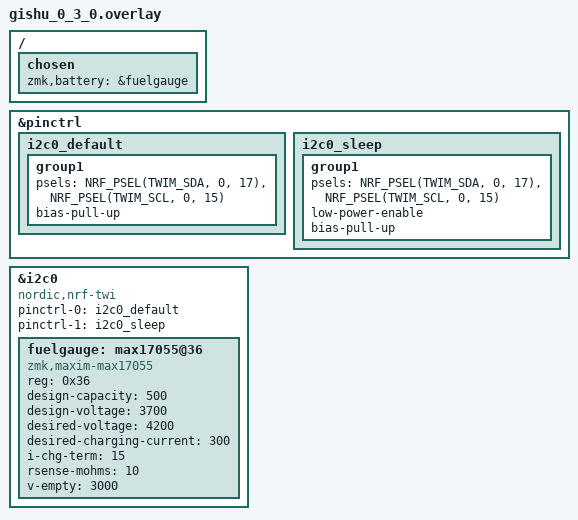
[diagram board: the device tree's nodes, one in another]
/ {
    chosen {
        zmk,battery = &fuelgauge;
    };
};

&pinctrl {
    i2c0_default: i2c0_default {
        group1 {
            psels = <NRF_PSEL(TWIM_SDA, 0, 17)>,
                    <NRF_PSEL(TWIM_SCL, 0, 15)>;
            bias-pull-up;
        };
    };

    i2c0_sleep: i2c0_sleep {
        group1 {
            psels = <NRF_PSEL(TWIM_SDA, 0, 17)>,
                    <NRF_PSEL(TWIM_SCL, 0, 15)>;
            low-power-enable;
            bias-pull-up;
        };
    };
};

&i2c0 {
    status = "okay";
    compatible = "nordic,nrf-twi";
    pinctrl-0 = <&i2c0_default>;
    pinctrl-1 = <&i2c0_sleep>;
    pinctrl-names = "default", "sleep";

    fuelgauge: max17055@36 {
        compatible = "zmk,maxim-max17055";
        reg = <0x36>;
        design-capacity = <500>;
        design-voltage = <3700>;
        desired-voltage = <4200>;
        desired-charging-current = <300>;
        i-chg-term = <15>;
        rsense-mohms = <10>;
        v-empty = <3000>;
    };

};
